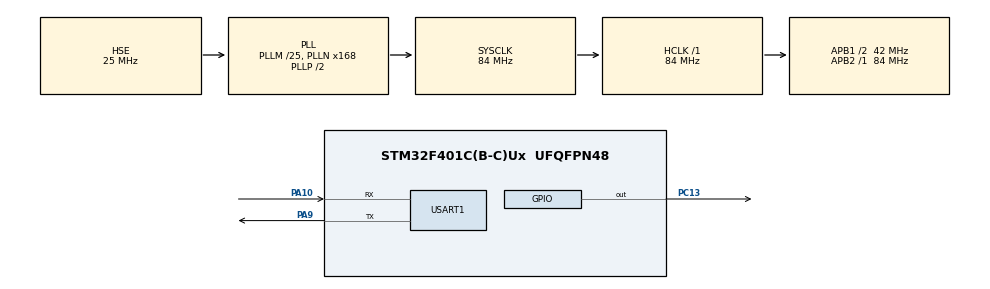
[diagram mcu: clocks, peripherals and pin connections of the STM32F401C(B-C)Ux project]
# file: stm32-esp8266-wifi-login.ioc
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FREERTOS.Tasks01=defaultTask,0,128,StartDefaultTask,Default,NULL,Dynamic,NULL,NULL;webViewTask,-3,2048,WebViewTask,Default,NULL,Dynamic,NULL,NULL
FREERTOS.configUSE_NEWLIB_REENTRANT=1
Mcu.Family=STM32F4
Mcu.Name=STM32F401C(B-C)Ux
Mcu.Package=UFQFPN48
NVIC.PriorityGroup=NVIC_PRIORITYGROUP_4
NVIC.TIM1_UP_TIM10_IRQn=true\:15\:0\:false\:false\:true\:false\:false\:true\:true
NVIC.TimeBase=TIM1_UP_TIM10_IRQn
NVIC.TimeBaseIP=TIM1
NVIC.USART1_IRQn=true\:5\:0\:false\:false\:true\:true\:true\:true\:true
PA10.Mode=Asynchronous
PA10.Signal=USART1_RX
PA13.Mode=Serial_Wire
PA13.Signal=SYS_JTMS-SWDIO
PA14.Mode=Serial_Wire
PA14.Signal=SYS_JTCK-SWCLK
PA9.Mode=Asynchronous
PA9.Signal=USART1_TX
PC13-ANTI_TAMP.Signal=GPIO_Output
PH0\ -\ OSC_IN.Mode=HSE-External-Oscillator
PH0\ -\ OSC_IN.Signal=RCC_OSC_IN
PH1\ -\ OSC_OUT.Mode=HSE-External-Oscillator
PH1\ -\ OSC_OUT.Signal=RCC_OSC_OUT
ProjectManager.HeapSize=0x200
ProjectManager.StackSize=0x400
ProjectManager.TargetToolchain=STM32CubeIDE
RCC.48MHZClocksFreq_Value=42000000
RCC.AHBFreq_Value=84000000
RCC.APB1CLKDivider=RCC_HCLK_DIV2
RCC.APB1Freq_Value=42000000
RCC.APB1TimFreq_Value=84000000
RCC.APB2Freq_Value=84000000
RCC.APB2TimFreq_Value=84000000
RCC.CortexFreq_Value=84000000
RCC.HCLKFreq_Value=84000000
RCC.HSE_VALUE=25000000
RCC.HSI_VALUE=16000000
RCC.LSE_VALUE=32768
RCC.PLLM=25
RCC.PLLN=168
RCC.PLLSourceVirtual=RCC_PLLSOURCE_HSE
RCC.SYSCLKFreq_VALUE=84000000
RCC.SYSCLKSource=RCC_SYSCLKSOURCE_PLLCLK
RCC.VCOOutputFreq_Value=168000000
USART1.VirtualMode=VM_ASYNC
VP_FREERTOS_VS_CMSIS_V1.Mode=CMSIS_V1
VP_SYS_VS_tim1.Mode=TIM1
board=custom

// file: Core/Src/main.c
/* USER CODE BEGIN Header */
/**
  ******************************************************************************
  * @file           : main.c
  * @brief          : Main program body
  ******************************************************************************
  * @attention
  *
  * Copyright (c) 2023 STMicroelectronics.
  * All rights reserved.
  *
  * This software is licensed under terms that can be found in the LICENSE file
  * in the root directory of this software component.
  * If no LICENSE file comes with this software, it is provided AS-IS.
  *
  ******************************************************************************
  */
/* USER CODE END Header */
#include "main.h"
#include "cmsis_os.h"

/* USER CODE BEGIN Includes */
#include "uart_isr_rx_tx.h"
#include "wifi_login_server.h"
/* USER CODE END Includes */

extern UART_HandleTypeDef huart1;

osThreadId defaultTaskHandle;
osThreadId webViewTaskHandle;

void SystemClock_Config(void);
static void MX_GPIO_Init(void);
static void MX_USART1_UART_Init(void);
void StartDefaultTask(void const * argument);
void WebViewTask(void const * argument);

int main(void)
{

  /* MCU Configuration--------------------------------------------------------*/

  /* Reset of all peripherals, Initializes the Flash interface and the Systick. */
  HAL_Init();

  /* Configure the system clock */
  SystemClock_Config();

  /* Initialize all configured peripherals */
  MX_GPIO_Init();
  MX_USART1_UART_Init();

  /* Create the thread(s) */
  /* definition and creation of defaultTask */
  osThreadDef(defaultTask, StartDefaultTask, osPriorityNormal, 0, 128);
  defaultTaskHandle = osThreadCreate(osThread(defaultTask), NULL);

  /* definition and creation of webViewTask */
  osThreadDef(webViewTask, WebViewTask, osPriorityIdle, 0, 2048);
  webViewTaskHandle = osThreadCreate(osThread(webViewTask), NULL);

  /* Start scheduler */
  osKernelStart();
  /* We should never get here as control is now taken by the scheduler */
  /* Infinite loop */
  while (1)
  {

  }
}

void SystemClock_Config(void)
{
  RCC_OscInitTypeDef RCC_OscInitStruct = {0};
  RCC_ClkInitTypeDef RCC_ClkInitStruct = {0};

  /** Configure the main internal regulator output voltage
  */
  __HAL_RCC_PWR_CLK_ENABLE();
  __HAL_PWR_VOLTAGESCALING_CONFIG(PWR_REGULATOR_VOLTAGE_SCALE2);

  /** Initializes the RCC Oscillators according to the specified parameters
  * in the RCC_OscInitTypeDef structure.
  */
  RCC_OscInitStruct.OscillatorType = RCC_OSCILLATORTYPE_HSE;
  RCC_OscInitStruct.HSEState = RCC_HSE_ON;
  RCC_OscInitStruct.PLL.PLLState = RCC_PLL_ON;
  RCC_OscInitStruct.PLL.PLLSource = RCC_PLLSOURCE_HSE;
  RCC_OscInitStruct.PLL.PLLM = 25;
  RCC_OscInitStruct.PLL.PLLN = 168;
  RCC_OscInitStruct.PLL.PLLP = RCC_PLLP_DIV2;
  RCC_OscInitStruct.PLL.PLLQ = 4;
  if (HAL_RCC_OscConfig(&RCC_OscInitStruct) != HAL_OK)
  {
    Error_Handler();
  }

  /** Initializes the CPU, AHB and APB buses clocks
  */
  RCC_ClkInitStruct.ClockType = RCC_CLOCKTYPE_HCLK|RCC_CLOCKTYPE_SYSCLK
                              |RCC_CLOCKTYPE_PCLK1|RCC_CLOCKTYPE_PCLK2;
  RCC_ClkInitStruct.SYSCLKSource = RCC_SYSCLKSOURCE_PLLCLK;
  RCC_ClkInitStruct.AHBCLKDivider = RCC_SYSCLK_DIV1;
  RCC_ClkInitStruct.APB1CLKDivider = RCC_HCLK_DIV2;
  RCC_ClkInitStruct.APB2CLKDivider = RCC_HCLK_DIV1;

  if (HAL_RCC_ClockConfig(&RCC_ClkInitStruct, FLASH_LATENCY_2) != HAL_OK)
  {
    Error_Handler();
  }
}

static void MX_USART1_UART_Init(void)
{

  huart1.Instance = USART1;
  huart1.Init.BaudRate = 115200;
  huart1.Init.WordLength = UART_WORDLENGTH_8B;
  huart1.Init.StopBits = UART_STOPBITS_1;
  huart1.Init.Parity = UART_PARITY_NONE;
  huart1.Init.Mode = UART_MODE_TX_RX;
  huart1.Init.HwFlowCtl = UART_HWCONTROL_NONE;
  huart1.Init.OverSampling = UART_OVERSAMPLING_16;
  if (HAL_UART_Init(&huart1) != HAL_OK)
  {
    Error_Handler();
  }

}

static void MX_GPIO_Init(void)
{
  GPIO_InitTypeDef GPIO_InitStruct = {0};

  /* GPIO Ports Clock Enable */
  __HAL_RCC_GPIOC_CLK_ENABLE();
  __HAL_RCC_GPIOH_CLK_ENABLE();
  __HAL_RCC_GPIOA_CLK_ENABLE();

  /*Configure GPIO pin Output Level */
  HAL_GPIO_WritePin(GPIOC, GPIO_PIN_13, GPIO_PIN_RESET);

  /*Configure GPIO pin : PC13 */
  GPIO_InitStruct.Pin = GPIO_PIN_13;
  GPIO_InitStruct.Mode = GPIO_MODE_OUTPUT_PP;
  GPIO_InitStruct.Pull = GPIO_NOPULL;
  GPIO_InitStruct.Speed = GPIO_SPEED_FREQ_LOW;
  HAL_GPIO_Init(GPIOC, &GPIO_InitStruct);

/* USER CODE BEGIN MX_GPIO_Init_2 */
  HAL_GPIO_WritePin(GPIOC, GPIO_PIN_13, GPIO_PIN_SET);
/* USER CODE END MX_GPIO_Init_2 */
}

void StartDefaultTask(void const * argument)
{
  for(;;)
  {
    osDelay(1);
  }
}

void WebViewTask(void const * argument)
{
  /* USER CODE BEGIN WebViewTask */
  start_http_web_server();
  /* Infinite loop */
  for(;;)
  {
	proc_http_web_server();
  }
  /* USER CODE END WebViewTask */
}

void HAL_TIM_PeriodElapsedCallback(TIM_HandleTypeDef *htim)
{
  if (htim->Instance == TIM1) {
    HAL_IncTick();
  }
}

void Error_Handler(void)
{
  __disable_irq();
  while (1)
  {
  }
}
